AUTOSAR XML (schema 4.0)
standard types defined: float32, float64, sint16, sint32, sint8, uint16, uint32, uint8, void, boolean
package /ImplDataTypes
  7 x impl type, all with category=TYPE_REFERENCE, type-emitter=RTE:
    Impl_IOPositionSensorReadingType: implementation-data-type=uint8
    Impl_IOWeightSensorReadingType: implementation-data-type=uint16
    Impl_SeatModeBtnType: implementation-data-type=uint8
    Impl_SensorPositionType: implementation-data-type=uint16
    Impl_SensorWeightType: implementation-data-type=uint16
    Impl_StepMotorStepType: implementation-data-type=uint32
    MultiStateBtnType: implementation-data-type=uint8
package /MappingSets
  data type mapping set MappingSet: mode-request-type-map{implementation-data-type=uint8, mode-group=SeatCtrlMode}
package /PortInterfaces/ClientServer
  6 x client server interface:
    CsIf_IOGetSensorPosition
      operation IOGet
        arg Arg_position: type=Impl_IOPositionSensorReadingType, direction=OUT
    CsIf_IOGetSensorWeight
      operation IOGet
        arg Arg_weight: type=Impl_IOWeightSensorReadingType, direction=OUT
    CsIf_IOSetMotor
      operation IOSetForward
      operation IOSetReverse
    CsIf_PositionSensor
      operation Opr_GetPosition
        arg Arg_position: type=Impl_SensorPositionType, direction=OUT
    CsIf_StepMotor
      operation Opr_Move
        arg Arg_step: type=Impl_StepMotorStepType, direction=IN
    CsIf_WeightSensor
      operation Opr_GetWeight
        arg Arg_weight: type=Impl_SensorWeightType, direction=OUT
package /PortInterfaces/ModeSwitch
  mode switch interface MsIf_SeatCtrlMode
    mode group SeatCtrlMode: type=SeatCtrlMode
  mode declaration group SeatCtrlMode: category=ALPHABETIC_ORDER, initial-mode=INIT, on-transition-value=255
    mode AUTO
    mode INIT
    mode MANUAL
package /PortInterfaces/SenderReceiver
  sender receiver interface SrIf_SeatCtrlBtns
    data DE_HeightBtnState: type=MultiStateBtnType
    data DE_InclineBtnState: type=MultiStateBtnType
    data DE_SlideBtnState: type=MultiStateBtnType
  sender receiver interface SrIf_SeatCtrlData
    data DE_Height: type=uint8
    data DE_Incline: type=uint8
    data DE_Slide: type=uint8
  sender receiver interface SrIf_SeatModeBtn
    data SeatModeBtn: type=Impl_SeatModeBtnType
package /SoftwareComponents
  10 x swc implementation, all with programming-language=C, sw-version=1.0.0, vendor-id=255:
    Impl_SWC_HMI: behavior=Ibhv_SWC_HMI
      code-descriptors:
        code Code: artifact-descriptors=autosar-engineering-object={short-label=SWC.c, category=SWSRC}
      resource consumption ResourceConsumption
    Impl_SWC_HeightMotor: behavior=Ibhv_SWC_HeightMotor
      code-descriptors:
        code Code: artifact-descriptors=autosar-engineering-object={short-label=SWC.c, category=SWSRC}
      resource consumption ResourceConsumption
    Impl_SWC_HeightSensor: behavior=Ibhv_SWC_HeightSensor
      code-descriptors:
        code Code: artifact-descriptors=autosar-engineering-object={short-label=SWC.c, category=SWSRC}
      resource consumption ResourceConsumption
    Impl_SWC_InclineMotor: behavior=Ibhv_SWC_InclineMotor
      code-descriptors:
        code Code: artifact-descriptors=autosar-engineering-object={short-label=SWC.c, category=SWSRC}
      resource consumption ResourceConsumption
    Impl_SWC_InclineSensor: behavior=Ibhv_SWC_InclineSensor
      code-descriptors:
        code Code: artifact-descriptors=autosar-engineering-object={short-label=SWC.c, category=SWSRC}
      resource consumption ResourceConsumption
    Impl_SWC_IohwAbs: behavior=Ibhv_SWC_IohwAbs
      code-descriptors:
        code Code: artifact-descriptors=autosar-engineering-object={short-label=SWC.c, category=SWSRC}
      resource consumption ResourceConsumption
    Impl_SWC_SeatManager: behavior=Ibhv_SWC_SeatManager
      code-descriptors:
        code Code: artifact-descriptors=autosar-engineering-object={short-label=SWC.c, category=SWSRC}
      resource consumption ResourceConsumption
    Impl_SWC_SlideMotor: behavior=Ibhv_SWC_SlideMotor
      code-descriptors:
        code Code: artifact-descriptors=autosar-engineering-object={short-label=SWC.c, category=SWSRC}
      resource consumption ResourceConsumption
    Impl_SWC_SlideSensor: behavior=Ibhv_SWC_SlideSensor
      code-descriptors:
        code Code: artifact-descriptors=autosar-engineering-object={short-label=SWC.c, category=SWSRC}
      resource consumption ResourceConsumption
    Impl_SWC_WeightSensor: behavior=Ibhv_SWC_WeightSensor
      code-descriptors:
        code Code: artifact-descriptors=autosar-engineering-object={short-label=SWC.c, category=SWSRC}
      resource consumption ResourceConsumption
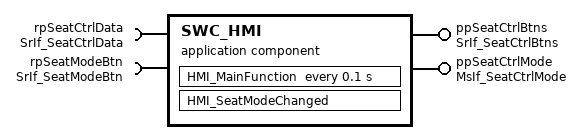
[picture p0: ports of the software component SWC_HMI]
  application sw component type SWC_HMI
    provide port ppSeatCtrlBtns: provided-interface=SrIf_SeatCtrlBtns
    provide port ppSeatCtrlMode: provided-interface=MsIf_SeatCtrlMode
    require port rpSeatCtrlData: required-interface=SrIf_SeatCtrlData
    require port rpSeatModeBtn: required-interface=SrIf_SeatModeBtn
    behavior Ibhv_SWC_HMI: data-type-mapping=MappingSet, handle-termination-and-restart=NO-SUPPORT
      data received event DRE_rpSeatModeBtn_SeatModeBtn: start-on-event=HMI_SeatModeChanged, data=rpSeatModeBtn.SeatModeBtn
      timing event TE_HMI_MainFunction_100ms: start-on-event=HMI_MainFunction, period=0.1
      runnable HMI_MainFunction
        data-receive-point-by-arguments:
          access DRP_rpSeatCtrlData_DE_Height: accessed-variable=rpSeatCtrlData.DE_Height
          access DRP_rpSeatCtrlData_DE_Incline: accessed-variable=rpSeatCtrlData.DE_Incline
          access DRP_rpSeatCtrlData_DE_Slide: accessed-variable=rpSeatCtrlData.DE_Slide
        data-send-points:
          access DSP_ppSeatCtrlBtns_DE_HeightBtnState: accessed-variable=ppSeatCtrlBtns.DE_HeightBtnState
          access DSP_ppSeatCtrlBtns_DE_InclineBtnState: accessed-variable=ppSeatCtrlBtns.DE_InclineBtnState
          access DSP_ppSeatCtrlBtns_DE_SlideBtnState: accessed-variable=ppSeatCtrlBtns.DE_SlideBtnState
      runnable HMI_SeatModeChanged
        data-receive-point-by-arguments:
          access DRP_rpSeatModeBtn_SeatModeBtn: accessed-variable=rpSeatModeBtn.SeatModeBtn
        mode switch point MSP_ppSeatCtrlMode_ppSeatCtrlMode: mode-group=ppSeatCtrlMode.SeatCtrlMode
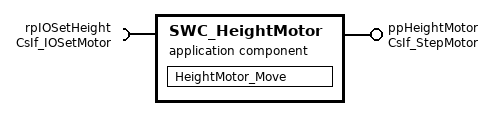
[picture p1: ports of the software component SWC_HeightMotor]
  application sw component type SWC_HeightMotor
    provide port ppHeightMotor: provided-interface=CsIf_StepMotor
    require port rpIOSetHeight: required-interface=CsIf_IOSetMotor
    behavior Ibhv_SWC_HeightMotor: data-type-mapping=MappingSet, handle-termination-and-restart=NO-SUPPORT
      operation invoked event OIE_ppHeightMotor_Opr_Move: start-on-event=HeightMotor_Move, operation=ppHeightMotor.Opr_Move
      runnable HeightMotor_Move
        sync call SCP_rpIOSetHeight_IOSetForward: operation=rpIOSetHeight.IOSetForward, timeout=0.0
        sync call SCP_rpIOSetHeight_IOSetReverse: operation=rpIOSetHeight.IOSetReverse, timeout=0.0
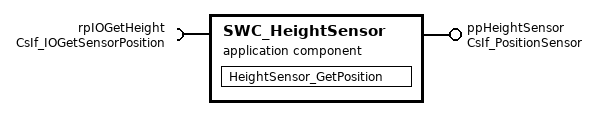
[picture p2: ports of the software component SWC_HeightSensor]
  application sw component type SWC_HeightSensor
    provide port ppHeightSensor: provided-interface=CsIf_PositionSensor
    require port rpIOGetHeight: required-interface=CsIf_IOGetSensorPosition
    behavior Ibhv_SWC_HeightSensor: data-type-mapping=MappingSet, handle-termination-and-restart=NO-SUPPORT
      operation invoked event OIE_ppHeightSensor_Opr_GetPosition: start-on-event=HeightSensor_GetPosition, operation=ppHeightSensor.Opr_GetPosition
      runnable HeightSensor_GetPosition
        sync call SCP_rpIOGetHeight_IOGet: operation=rpIOGetHeight.IOGet, timeout=0.0
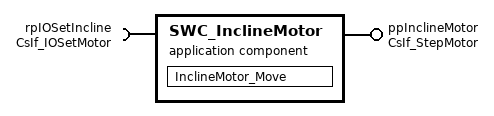
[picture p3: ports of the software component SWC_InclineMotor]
  application sw component type SWC_InclineMotor
    provide port ppInclineMotor: provided-interface=CsIf_StepMotor
    require port rpIOSetIncline: required-interface=CsIf_IOSetMotor
    behavior Ibhv_SWC_InclineMotor: data-type-mapping=MappingSet, handle-termination-and-restart=NO-SUPPORT
      operation invoked event OIE_ppInclineMotor_Opr_Move: start-on-event=InclineMotor_Move, operation=ppInclineMotor.Opr_Move
      runnable InclineMotor_Move
        sync call SCP_rpIOSetIncline_IOSetForward: operation=rpIOSetIncline.IOSetForward, timeout=0.0
        sync call SCP_rpIOSetIncline_IOSetReverse: operation=rpIOSetIncline.IOSetReverse, timeout=0.0
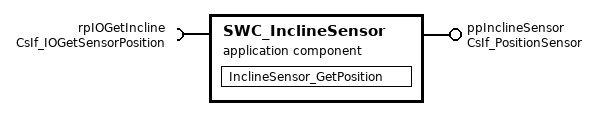
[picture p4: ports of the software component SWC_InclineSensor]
  application sw component type SWC_InclineSensor
    provide port ppInclineSensor: provided-interface=CsIf_PositionSensor
    require port rpIOGetIncline: required-interface=CsIf_IOGetSensorPosition
    behavior Ibhv_SWC_InclineSensor: data-type-mapping=MappingSet, handle-termination-and-restart=NO-SUPPORT
      operation invoked event OIE_ppInclineSensor_Opr_GetPosition: start-on-event=InclineSensor_GetPosition, operation=ppInclineSensor.Opr_GetPosition
      runnable InclineSensor_GetPosition
        sync call SCP_rpIOGetIncline_IOGet: operation=rpIOGetIncline.IOGet, timeout=0.0
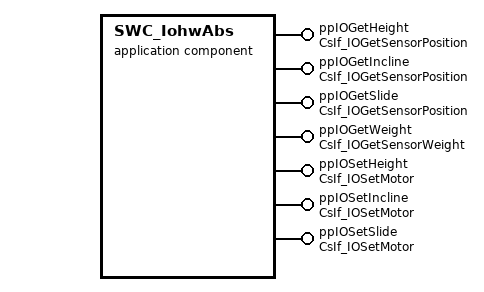
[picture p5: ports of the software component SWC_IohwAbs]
  application sw component type SWC_IohwAbs
    7 x provide port:
      ppIOGetHeight: provided-interface=CsIf_IOGetSensorPosition
      ppIOGetIncline: provided-interface=CsIf_IOGetSensorPosition
      ppIOGetSlide: provided-interface=CsIf_IOGetSensorPosition
      ppIOGetWeight: provided-interface=CsIf_IOGetSensorWeight
      ppIOSetHeight: provided-interface=CsIf_IOSetMotor
      ppIOSetIncline: provided-interface=CsIf_IOSetMotor
      ppIOSetSlide: provided-interface=CsIf_IOSetMotor
    behavior Ibhv_SWC_IohwAbs: data-type-mapping=MappingSet, handle-termination-and-restart=NO-SUPPORT
      10 x operation invoked event:
        OIE_ppIOGetHeight_IOGet: start-on-event=IoHwAbs_ECUGet_Height, operation=ppIOGetHeight.IOGet
        OIE_ppIOGetIncline_IOGet: start-on-event=IoHwAbs_ECUGet_Incline, operation=ppIOGetIncline.IOGet
        OIE_ppIOGetSlide_IOGet: start-on-event=IoHwAbs_ECUGet_Slide, operation=ppIOGetSlide.IOGet
        OIE_ppIOGetWeight_IOGet: start-on-event=IoHwAbs_ECUGet_Weight, operation=ppIOGetWeight.IOGet
        OIE_ppIOSetHeight_IOSetForward: start-on-event=IoHwAbs_ECUSetForward_Height, operation=ppIOSetHeight.IOSetForward
        OIE_ppIOSetHeight_IOSetReverse: start-on-event=IoHwAbs_ECUSetReverse_Height, operation=ppIOSetHeight.IOSetReverse
        OIE_ppIOSetIncline_IOSetForward: start-on-event=IoHwAbs_ECUSetForward_Incline, operation=ppIOSetIncline.IOSetForward
        OIE_ppIOSetIncline_IOSetReverse: start-on-event=IoHwAbs_ECUSetReverse_Incline, operation=ppIOSetIncline.IOSetReverse
        OIE_ppIOSetSlide_IOSetForward: start-on-event=IoHwAbs_ECUSetForward_Slide, operation=ppIOSetSlide.IOSetForward
        OIE_ppIOSetSlide_IOSetReverse: start-on-event=IoHwAbs_ECUSetReverse_Slide, operation=ppIOSetSlide.IOSetReverse
      10 x runnable:
        IoHwAbs_ECUGet_Height
        IoHwAbs_ECUGet_Incline
        IoHwAbs_ECUGet_Slide
        IoHwAbs_ECUGet_Weight
        IoHwAbs_ECUSetForward_Height
        IoHwAbs_ECUSetForward_Incline
        IoHwAbs_ECUSetForward_Slide
        IoHwAbs_ECUSetReverse_Height
        IoHwAbs_ECUSetReverse_Incline
        IoHwAbs_ECUSetReverse_Slide
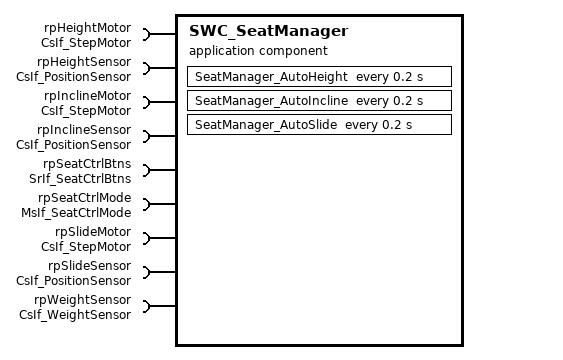
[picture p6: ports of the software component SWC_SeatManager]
  application sw component type SWC_SeatManager
    9 x require port:
      rpHeightMotor: required-interface=CsIf_StepMotor
      rpHeightSensor: required-interface=CsIf_PositionSensor
      rpInclineMotor: required-interface=CsIf_StepMotor
      rpInclineSensor: required-interface=CsIf_PositionSensor
      rpSeatCtrlBtns: required-interface=SrIf_SeatCtrlBtns
      rpSeatCtrlMode: required-interface=MsIf_SeatCtrlMode
      rpSlideMotor: required-interface=CsIf_StepMotor
      rpSlideSensor: required-interface=CsIf_PositionSensor
      rpWeightSensor: required-interface=CsIf_WeightSensor
    behavior Ibhv_SWC_SeatManager: data-type-mapping=MappingSet, handle-termination-and-restart=NO-SUPPORT
      data received event DRE_rpSeatCtrlBtns_DE_HeightBtnState: start-on-event=SeatManager_SetHeight, data=rpSeatCtrlBtns.DE_HeightBtnState
      data received event DRE_rpSeatCtrlBtns_DE_InclineBtnState: start-on-event=SeatManager_SetIncline, data=rpSeatCtrlBtns.DE_InclineBtnState
      data received event DRE_rpSeatCtrlBtns_DE_SlideBtnState: start-on-event=SeatManager_SetSlide, data=rpSeatCtrlBtns.DE_SlideBtnState
      timing event TE_SeatManager_AutoHeight_200ms: start-on-event=SeatManager_AutoHeight, period=0.2
      timing event TE_SeatManager_AutoIncline_200ms: start-on-event=SeatManager_AutoIncline, period=0.2
      timing event TE_SeatManager_AutoSlide_200ms: start-on-event=SeatManager_AutoSlide, period=0.2
      6 x runnable:
        SeatManager_AutoHeight
          sync call SCP_rpHeightMotor_Opr_Move: operation=rpHeightMotor.Opr_Move, timeout=0.0
          sync call SCP_rpHeightSensor_Opr_GetPosition: operation=rpHeightSensor.Opr_GetPosition, timeout=0.0
          sync call SCP_rpWeightSensor_Opr_GetWeight: operation=rpWeightSensor.Opr_GetWeight, timeout=0.0
        SeatManager_AutoIncline
          sync call SCP_rpInclineMotor_Opr_Move: operation=rpInclineMotor.Opr_Move, timeout=0.0
          sync call SCP_rpInclineSensor_Opr_GetPosition: operation=rpInclineSensor.Opr_GetPosition, timeout=0.0
          sync call SCP_rpWeightSensor_Opr_GetWeight: operation=rpWeightSensor.Opr_GetWeight, timeout=0.0
        SeatManager_AutoSlide
          sync call SCP_rpSlideMotor_Opr_Move: operation=rpSlideMotor.Opr_Move, timeout=0.0
          sync call SCP_rpSlideSensor_Opr_GetPosition: operation=rpSlideSensor.Opr_GetPosition, timeout=0.0
          sync call SCP_rpWeightSensor_Opr_GetWeight: operation=rpWeightSensor.Opr_GetWeight, timeout=0.0
        SeatManager_SetHeight
          data-receive-point-by-arguments:
            access DRP_rpSeatCtrlBtns_DE_HeightBtnState: accessed-variable=rpSeatCtrlBtns.DE_HeightBtnState
          sync call SCP_rpHeightMotor_Opr_Move: operation=rpHeightMotor.Opr_Move, timeout=0.0
        SeatManager_SetIncline
          data-receive-point-by-arguments:
            access DRP_rpSeatCtrlBtns_DE_InclineBtnState: accessed-variable=rpSeatCtrlBtns.DE_InclineBtnState
          sync call SCP_rpSlideMotor_Opr_Move: operation=rpSlideMotor.Opr_Move, timeout=0.0
        SeatManager_SetSlide
          data-receive-point-by-arguments:
            access DRP_rpSeatCtrlBtns_DE_SlideBtnState: accessed-variable=rpSeatCtrlBtns.DE_SlideBtnState
          sync call SCP_rpInclineMotor_Opr_Move: operation=rpInclineMotor.Opr_Move, timeout=0.0
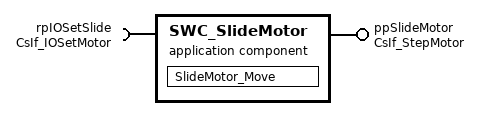
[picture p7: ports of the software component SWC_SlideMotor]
  application sw component type SWC_SlideMotor
    provide port ppSlideMotor: provided-interface=CsIf_StepMotor
    require port rpIOSetSlide: required-interface=CsIf_IOSetMotor
    behavior Ibhv_SWC_SlideMotor: data-type-mapping=MappingSet, handle-termination-and-restart=NO-SUPPORT
      operation invoked event OIE_ppSlideMotor_Opr_Move: start-on-event=SlideMotor_Move, operation=ppSlideMotor.Opr_Move
      runnable SlideMotor_Move
        sync call SCP_rpIOSetSlide_IOSetForward: operation=rpIOSetSlide.IOSetForward, timeout=0.0
        sync call SCP_rpIOSetSlide_IOSetReverse: operation=rpIOSetSlide.IOSetReverse, timeout=0.0
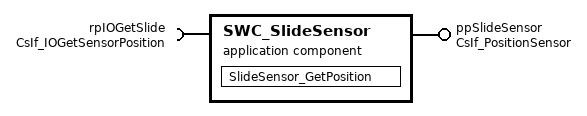
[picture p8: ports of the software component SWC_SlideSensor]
  application sw component type SWC_SlideSensor
    provide port ppSlideSensor: provided-interface=CsIf_PositionSensor
    require port rpIOGetSlide: required-interface=CsIf_IOGetSensorPosition
    behavior Ibhv_SWC_SlideSensor: data-type-mapping=MappingSet, handle-termination-and-restart=NO-SUPPORT
      operation invoked event OIE_ppSlideSensor_Opr_GetPosition: start-on-event=SlideSensor_GetPosition, operation=ppSlideSensor.Opr_GetPosition
      runnable SlideSensor_GetPosition
        sync call SCP_rpIOGetSlide_IOGet: operation=rpIOGetSlide.IOGet, timeout=0.0
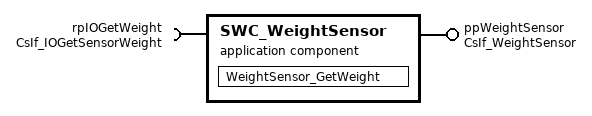
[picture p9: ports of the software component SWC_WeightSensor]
  application sw component type SWC_WeightSensor
    provide port ppWeightSensor: provided-interface=CsIf_WeightSensor
    require port rpIOGetWeight: required-interface=CsIf_IOGetSensorWeight
    behavior Ibhv_SWC_WeightSensor: data-type-mapping=MappingSet, handle-termination-and-restart=NO-SUPPORT
      operation invoked event OIE_ppWeightSensor_Opr_GetWeight: start-on-event=WeightSensor_GetWeight, operation=ppWeightSensor.Opr_GetWeight
      runnable WeightSensor_GetWeight
        sync call SCP_rpIOGetWeight_IOGet: operation=rpIOGetWeight.IOGet, timeout=0.0
package /Compositions
  composition sw component type TestAppComposition
    10 x component:
      SWC_HMI: type=SWC_HMI
      SWC_HeightMotor: type=SWC_HeightMotor
      SWC_HeightSensor: type=SWC_HeightSensor
      SWC_InclineMotor: type=SWC_InclineMotor
      SWC_InclineSensor: type=SWC_InclineSensor
      SWC_IohwAbs: type=SWC_IohwAbs
      SWC_SeatManager: type=SWC_SeatManager
      SWC_SlideMotor: type=SWC_SlideMotor
      SWC_SlideSensor: type=SWC_SlideSensor
      SWC_WeightSensor: type=SWC_WeightSensor
    connect SWC_HMI.ppSeatCtrlBtns -> SWC_SeatManager.rpSeatCtrlBtns
    connect SWC_HMI.ppSeatCtrlMode -> SWC_SeatManager.rpSeatCtrlMode
    connect SWC_HeightMotor.ppHeightMotor -> SWC_SeatManager.rpHeightMotor
    connect SWC_HeightSensor.ppHeightSensor -> SWC_SeatManager.rpHeightSensor
    connect SWC_InclineMotor.ppInclineMotor -> SWC_SeatManager.rpInclineMotor
    connect SWC_InclineSensor.ppInclineSensor -> SWC_SeatManager.rpInclineSensor
    connect SWC_IohwAbs.ppIOGetHeight -> SWC_HeightSensor.rpIOGetHeight
    connect SWC_IohwAbs.ppIOGetIncline -> SWC_InclineSensor.rpIOGetIncline
    connect SWC_IohwAbs.ppIOGetSlide -> SWC_SlideSensor.rpIOGetSlide
    connect SWC_IohwAbs.ppIOGetWeight -> SWC_WeightSensor.rpIOGetWeight
    connect SWC_IohwAbs.ppIOSetHeight -> SWC_HeightMotor.rpIOSetHeight
    connect SWC_IohwAbs.ppIOSetIncline -> SWC_InclineMotor.rpIOSetIncline
    connect SWC_IohwAbs.ppIOSetSlide -> SWC_SlideMotor.rpIOSetSlide
    connect SWC_SlideMotor.ppSlideMotor -> SWC_SeatManager.rpSlideMotor
    connect SWC_SlideSensor.ppSlideSensor -> SWC_SeatManager.rpSlideSensor
    connect SWC_WeightSensor.ppWeightSensor -> SWC_SeatManager.rpWeightSensor
